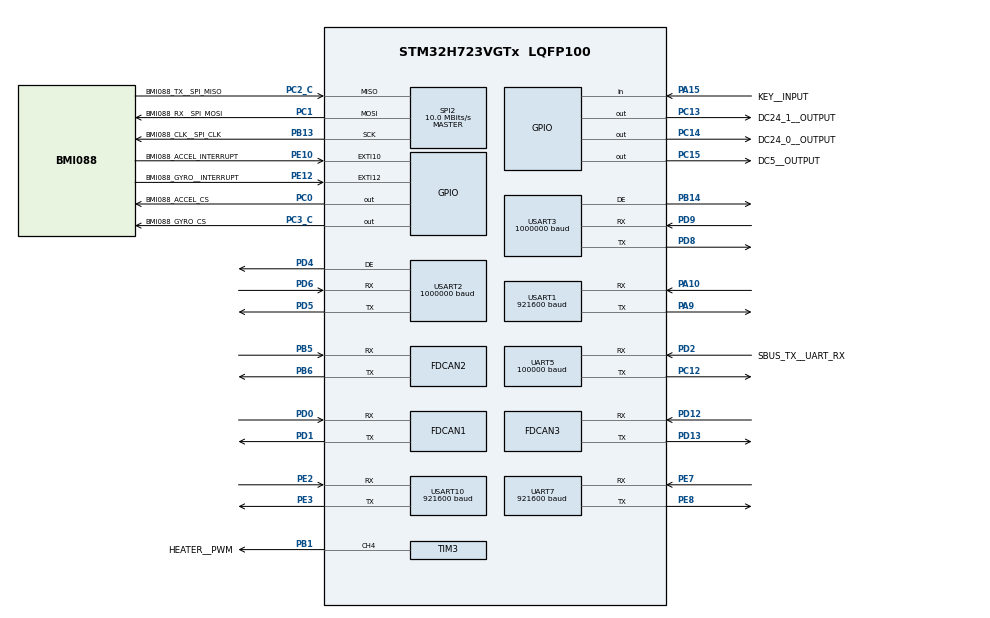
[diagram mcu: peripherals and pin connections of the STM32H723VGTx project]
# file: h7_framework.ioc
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CORTEX_M7.BaseAddress_Spec=0x24000000
CORTEX_M7.CPU_DCache=Disabled
CORTEX_M7.CPU_ICache=Enabled
CORTEX_M7.DisableExec_Spec=MPU_INSTRUCTION_ACCESS_ENABLE
CORTEX_M7.IsBufferable_Spec=MPU_ACCESS_BUFFERABLE
CORTEX_M7.IsCacheable_Spec=MPU_ACCESS_CACHEABLE
CORTEX_M7.IsShareable_Spec=MPU_ACCESS_NOT_SHAREABLE
CORTEX_M7.MPU_Control=__NULL
CORTEX_M7.Size_Spec=MPU_REGION_SIZE_512KB
CORTEX_M7.SubRegionDisable_Spec=0x0
CORTEX_M7.TypeExtField_Spec=MPU_TEX_LEVEL1
CORTEX_M7.default_mode_Activation=1
Dma.Request0=USART2_RX
Dma.Request1=USART2_TX
Dma.Request10=USART10_TX
Dma.Request11=SPI2_RX
Dma.Request12=SPI2_TX
Dma.Request2=USART3_RX
Dma.Request3=USART3_TX
Dma.Request4=UART5_RX
Dma.Request5=USART1_RX
Dma.Request6=USART1_TX
Dma.Request7=UART7_RX
Dma.Request8=UART7_TX
Dma.Request9=USART10_RX
Dma.SPI2_RX.11.Direction=DMA_PERIPH_TO_MEMORY
Dma.SPI2_RX.11.EventEnable=DISABLE
Dma.SPI2_RX.11.FIFOMode=DMA_FIFOMODE_ENABLE
Dma.SPI2_RX.11.FIFOThreshold=DMA_FIFO_THRESHOLD_FULL
Dma.SPI2_RX.11.Instance=DMA2_Stream3
Dma.SPI2_RX.11.MemBurst=DMA_MBURST_SINGLE
Dma.SPI2_RX.11.MemDataAlignment=DMA_MDATAALIGN_BYTE
Dma.SPI2_RX.11.MemInc=DMA_MINC_ENABLE
Dma.SPI2_RX.11.Mode=DMA_NORMAL
Dma.SPI2_RX.11.PeriphBurst=DMA_PBURST_SINGLE
Dma.SPI2_RX.11.PeriphDataAlignment=DMA_PDATAALIGN_BYTE
Dma.SPI2_RX.11.PeriphInc=DMA_PINC_DISABLE
Dma.SPI2_RX.11.Polarity=HAL_DMAMUX_REQ_GEN_RISING
Dma.SPI2_RX.11.Priority=DMA_PRIORITY_LOW
Dma.SPI2_RX.11.RequestNumber=1
Dma.SPI2_RX.11.SignalID=NONE
Dma.SPI2_RX.11.SyncEnable=DISABLE
Dma.SPI2_RX.11.SyncPolarity=HAL_DMAMUX_SYNC_NO_EVENT
Dma.SPI2_RX.11.SyncRequestNumber=1
Dma.SPI2_RX.11.SyncSignalID=NONE
Dma.SPI2_TX.12.Direction=DMA_MEMORY_TO_PERIPH
Dma.SPI2_TX.12.EventEnable=DISABLE
Dma.SPI2_TX.12.FIFOMode=DMA_FIFOMODE_DISABLE
Dma.SPI2_TX.12.Instance=DMA2_Stream4
Dma.SPI2_TX.12.MemDataAlignment=DMA_MDATAALIGN_BYTE
Dma.SPI2_TX.12.MemInc=DMA_MINC_ENABLE
Dma.SPI2_TX.12.Mode=DMA_NORMAL
Dma.SPI2_TX.12.PeriphDataAlignment=DMA_PDATAALIGN_BYTE
Dma.SPI2_TX.12.PeriphInc=DMA_PINC_DISABLE
Dma.SPI2_TX.12.Polarity=HAL_DMAMUX_REQ_GEN_RISING
Dma.SPI2_TX.12.Priority=DMA_PRIORITY_LOW
Dma.SPI2_TX.12.RequestNumber=1
Dma.SPI2_TX.12.SignalID=NONE
Dma.SPI2_TX.12.SyncEnable=DISABLE
Dma.SPI2_TX.12.SyncPolarity=HAL_DMAMUX_SYNC_NO_EVENT
Dma.SPI2_TX.12.SyncRequestNumber=1
Dma.SPI2_TX.12.SyncSignalID=NONE
Dma.UART5_RX.4.Direction=DMA_PERIPH_TO_MEMORY
Dma.UART5_RX.4.EventEnable=DISABLE
Dma.UART5_RX.4.FIFOMode=DMA_FIFOMODE_ENABLE
Dma.UART5_RX.4.FIFOThreshold=DMA_FIFO_THRESHOLD_FULL
Dma.UART5_RX.4.Instance=DMA1_Stream4
Dma.UART5_RX.4.MemBurst=DMA_MBURST_SINGLE
Dma.UART5_RX.4.MemDataAlignment=DMA_MDATAALIGN_BYTE
Dma.UART5_RX.4.MemInc=DMA_MINC_ENABLE
Dma.UART5_RX.4.Mode=DMA_NORMAL
Dma.UART5_RX.4.PeriphBurst=DMA_PBURST_SINGLE
Dma.UART5_RX.4.PeriphDataAlignment=DMA_PDATAALIGN_BYTE
Dma.UART5_RX.4.PeriphInc=DMA_PINC_DISABLE
Dma.UART5_RX.4.Polarity=HAL_DMAMUX_REQ_GEN_RISING
Dma.UART5_RX.4.Priority=DMA_PRIORITY_LOW
Dma.UART5_RX.4.RequestNumber=1
Dma.UART5_RX.4.SignalID=NONE
Dma.UART5_RX.4.SyncEnable=DISABLE
Dma.UART5_RX.4.SyncPolarity=HAL_DMAMUX_SYNC_NO_EVENT
Dma.UART5_RX.4.SyncRequestNumber=1
Dma.UART5_RX.4.SyncSignalID=NONE
Dma.UART7_RX.7.Direction=DMA_PERIPH_TO_MEMORY
Dma.UART7_RX.7.EventEnable=DISABLE
Dma.UART7_RX.7.FIFOMode=DMA_FIFOMODE_ENABLE
Dma.UART7_RX.7.FIFOThreshold=DMA_FIFO_THRESHOLD_FULL
Dma.UART7_RX.7.Instance=DMA1_Stream7
Dma.UART7_RX.7.MemBurst=DMA_MBURST_SINGLE
Dma.UART7_RX.7.MemDataAlignment=DMA_MDATAALIGN_BYTE
Dma.UART7_RX.7.MemInc=DMA_MINC_ENABLE
Dma.UART7_RX.7.Mode=DMA_NORMAL
Dma.UART7_RX.7.PeriphBurst=DMA_PBURST_SINGLE
Dma.UART7_RX.7.PeriphDataAlignment=DMA_PDATAALIGN_BYTE
Dma.UART7_RX.7.PeriphInc=DMA_PINC_DISABLE
Dma.UART7_RX.7.Polarity=HAL_DMAMUX_REQ_GEN_RISING
Dma.UART7_RX.7.Priority=DMA_PRIORITY_LOW
Dma.UART7_RX.7.RequestNumber=1
Dma.UART7_RX.7.SignalID=NONE
Dma.UART7_RX.7.SyncEnable=DISABLE
Dma.UART7_RX.7.SyncPolarity=HAL_DMAMUX_SYNC_NO_EVENT
Dma.UART7_RX.7.SyncRequestNumber=1
Dma.UART7_RX.7.SyncSignalID=NONE
Dma.UART7_TX.8.Direction=DMA_MEMORY_TO_PERIPH
Dma.UART7_TX.8.EventEnable=DISABLE
Dma.UART7_TX.8.FIFOMode=DMA_FIFOMODE_ENABLE
Dma.UART7_TX.8.FIFOThreshold=DMA_FIFO_THRESHOLD_FULL
Dma.UART7_TX.8.Instance=DMA2_Stream0
Dma.UART7_TX.8.MemBurst=DMA_MBURST_SINGLE
Dma.UART7_TX.8.MemDataAlignment=DMA_MDATAALIGN_BYTE
Dma.UART7_TX.8.MemInc=DMA_MINC_ENABLE
Dma.UART7_TX.8.Mode=DMA_NORMAL
Dma.UART7_TX.8.PeriphBurst=DMA_PBURST_SINGLE
Dma.UART7_TX.8.PeriphDataAlignment=DMA_PDATAALIGN_BYTE
Dma.UART7_TX.8.PeriphInc=DMA_PINC_DISABLE
Dma.UART7_TX.8.Polarity=HAL_DMAMUX_REQ_GEN_RISING
Dma.UART7_TX.8.Priority=DMA_PRIORITY_LOW
Dma.UART7_TX.8.RequestNumber=1
Dma.UART7_TX.8.SignalID=NONE
Dma.UART7_TX.8.SyncEnable=DISABLE
Dma.UART7_TX.8.SyncPolarity=HAL_DMAMUX_SYNC_NO_EVENT
Dma.UART7_TX.8.SyncRequestNumber=1
Dma.UART7_TX.8.SyncSignalID=NONE
Dma.USART10_RX.9.Direction=DMA_PERIPH_TO_MEMORY
Dma.USART10_RX.9.EventEnable=DISABLE
Dma.USART10_RX.9.FIFOMode=DMA_FIFOMODE_DISABLE
Dma.USART10_RX.9.Instance=DMA2_Stream1
Dma.USART10_RX.9.MemDataAlignment=DMA_MDATAALIGN_BYTE
Dma.USART10_RX.9.MemInc=DMA_MINC_ENABLE
Dma.USART10_RX.9.Mode=DMA_NORMAL
Dma.USART10_RX.9.PeriphDataAlignment=DMA_PDATAALIGN_BYTE
Dma.USART10_RX.9.PeriphInc=DMA_PINC_DISABLE
Dma.USART10_RX.9.Polarity=HAL_DMAMUX_REQ_GEN_RISING
Dma.USART10_RX.9.Priority=DMA_PRIORITY_LOW
Dma.USART10_RX.9.RequestNumber=1
Dma.USART10_RX.9.SignalID=NONE
Dma.USART10_RX.9.SyncEnable=DISABLE
Dma.USART10_RX.9.SyncPolarity=HAL_DMAMUX_SYNC_NO_EVENT
Dma.USART10_RX.9.SyncRequestNumber=1
Dma.USART10_RX.9.SyncSignalID=NONE
Dma.USART10_TX.10.Direction=DMA_MEMORY_TO_PERIPH
Dma.USART10_TX.10.EventEnable=DISABLE
Dma.USART10_TX.10.FIFOMode=DMA_FIFOMODE_DISABLE
Dma.USART10_TX.10.Instance=DMA2_Stream2
Dma.USART10_TX.10.MemDataAlignment=DMA_MDATAALIGN_BYTE
Dma.USART10_TX.10.MemInc=DMA_MINC_ENABLE
Dma.USART10_TX.10.Mode=DMA_NORMAL
Dma.USART10_TX.10.PeriphDataAlignment=DMA_PDATAALIGN_BYTE
Dma.USART10_TX.10.PeriphInc=DMA_PINC_DISABLE
Dma.USART10_TX.10.Polarity=HAL_DMAMUX_REQ_GEN_RISING
Dma.USART10_TX.10.Priority=DMA_PRIORITY_LOW
Dma.USART10_TX.10.RequestNumber=1
Dma.USART10_TX.10.SignalID=NONE
Dma.USART10_TX.10.SyncEnable=DISABLE
Dma.USART10_TX.10.SyncPolarity=HAL_DMAMUX_SYNC_NO_EVENT
Dma.USART10_TX.10.SyncRequestNumber=1
Dma.USART10_TX.10.SyncSignalID=NONE
Dma.USART1_RX.5.Direction=DMA_PERIPH_TO_MEMORY
Dma.USART1_RX.5.EventEnable=DISABLE
Dma.USART1_RX.5.FIFOMode=DMA_FIFOMODE_ENABLE
Dma.USART1_RX.5.FIFOThreshold=DMA_FIFO_THRESHOLD_FULL
Dma.USART1_RX.5.Instance=DMA1_Stream5
Dma.USART1_RX.5.MemBurst=DMA_MBURST_SINGLE
Dma.USART1_RX.5.MemDataAlignment=DMA_MDATAALIGN_BYTE
Dma.USART1_RX.5.MemInc=DMA_MINC_ENABLE
Dma.USART1_RX.5.Mode=DMA_NORMAL
Dma.USART1_RX.5.PeriphBurst=DMA_PBURST_SINGLE
Dma.USART1_RX.5.PeriphDataAlignment=DMA_PDATAALIGN_BYTE
Dma.USART1_RX.5.PeriphInc=DMA_PINC_DISABLE
Dma.USART1_RX.5.Polarity=HAL_DMAMUX_REQ_GEN_RISING
Dma.USART1_RX.5.Priority=DMA_PRIORITY_LOW
Dma.USART1_RX.5.RequestNumber=1
Dma.USART1_RX.5.SignalID=NONE
Dma.USART1_RX.5.SyncEnable=DISABLE
Dma.USART1_RX.5.SyncPolarity=HAL_DMAMUX_SYNC_NO_EVENT
Dma.USART1_RX.5.SyncRequestNumber=1
Dma.USART1_RX.5.SyncSignalID=NONE
Dma.USART1_TX.6.Direction=DMA_MEMORY_TO_PERIPH
Dma.USART1_TX.6.EventEnable=DISABLE
Dma.USART1_TX.6.FIFOMode=DMA_FIFOMODE_ENABLE
Dma.USART1_TX.6.FIFOThreshold=DMA_FIFO_THRESHOLD_FULL
Dma.USART1_TX.6.Instance=DMA1_Stream6
Dma.USART1_TX.6.MemBurst=DMA_MBURST_SINGLE
Dma.USART1_TX.6.MemDataAlignment=DMA_MDATAALIGN_BYTE
Dma.USART1_TX.6.MemInc=DMA_MINC_ENABLE
Dma.USART1_TX.6.Mode=DMA_NORMAL
Dma.USART1_TX.6.PeriphBurst=DMA_PBURST_SINGLE
Dma.USART1_TX.6.PeriphDataAlignment=DMA_PDATAALIGN_BYTE
Dma.USART1_TX.6.PeriphInc=DMA_PINC_DISABLE
Dma.USART1_TX.6.Polarity=HAL_DMAMUX_REQ_GEN_RISING
Dma.USART1_TX.6.Priority=DMA_PRIORITY_LOW
Dma.USART1_TX.6.RequestNumber=1
Dma.USART1_TX.6.SignalID=NONE
Dma.USART1_TX.6.SyncEnable=DISABLE
Dma.USART1_TX.6.SyncPolarity=HAL_DMAMUX_SYNC_NO_EVENT
Dma.USART1_TX.6.SyncRequestNumber=1
Dma.USART1_TX.6.SyncSignalID=NONE
Dma.USART2_RX.0.Direction=DMA_PERIPH_TO_MEMORY
Dma.USART2_RX.0.EventEnable=DISABLE
Dma.USART2_RX.0.FIFOMode=DMA_FIFOMODE_ENABLE
Dma.USART2_RX.0.FIFOThreshold=DMA_FIFO_THRESHOLD_FULL
Dma.USART2_RX.0.Instance=DMA1_Stream1
Dma.USART2_RX.0.MemBurst=DMA_MBURST_SINGLE
Dma.USART2_RX.0.MemDataAlignment=DMA_MDATAALIGN_BYTE
Dma.USART2_RX.0.MemInc=DMA_MINC_ENABLE
Dma.USART2_RX.0.Mode=DMA_NORMAL
Dma.USART2_RX.0.PeriphBurst=DMA_PBURST_SINGLE
Dma.USART2_RX.0.PeriphDataAlignment=DMA_PDATAALIGN_BYTE
Dma.USART2_RX.0.PeriphInc=DMA_PINC_DISABLE
Dma.USART2_RX.0.Polarity=HAL_DMAMUX_REQ_GEN_RISING
Dma.USART2_RX.0.Priority=DMA_PRIORITY_LOW
Dma.USART2_RX.0.RequestNumber=1
Dma.USART2_RX.0.SignalID=NONE
Dma.USART2_RX.0.SyncEnable=DISABLE
Dma.USART2_RX.0.SyncPolarity=HAL_DMAMUX_SYNC_NO_EVENT
Dma.USART2_RX.0.SyncRequestNumber=1
Dma.USART2_RX.0.SyncSignalID=NONE
Dma.USART2_TX.1.Direction=DMA_MEMORY_TO_PERIPH
Dma.USART2_TX.1.EventEnable=DISABLE
Dma.USART2_TX.1.FIFOMode=DMA_FIFOMODE_ENABLE
Dma.USART2_TX.1.FIFOThreshold=DMA_FIFO_THRESHOLD_FULL
Dma.USART2_TX.1.Instance=DMA1_Stream0
Dma.USART2_TX.1.MemBurst=DMA_MBURST_SINGLE
Dma.USART2_TX.1.MemDataAlignment=DMA_MDATAALIGN_BYTE
Dma.USART2_TX.1.MemInc=DMA_MINC_ENABLE
Dma.USART2_TX.1.Mode=DMA_NORMAL
Dma.USART2_TX.1.PeriphBurst=DMA_PBURST_SINGLE
Dma.USART2_TX.1.PeriphDataAlignment=DMA_PDATAALIGN_BYTE
Dma.USART2_TX.1.PeriphInc=DMA_PINC_DISABLE
Dma.USART2_TX.1.Polarity=HAL_DMAMUX_REQ_GEN_RISING
Dma.USART2_TX.1.Priority=DMA_PRIORITY_LOW
Dma.USART2_TX.1.RequestNumber=1
Dma.USART2_TX.1.SignalID=NONE
Dma.USART2_TX.1.SyncEnable=DISABLE
Dma.USART2_TX.1.SyncPolarity=HAL_DMAMUX_SYNC_NO_EVENT
Dma.USART2_TX.1.SyncRequestNumber=1
Dma.USART2_TX.1.SyncSignalID=NONE
Dma.USART3_RX.2.Direction=DMA_PERIPH_TO_MEMORY
Dma.USART3_RX.2.EventEnable=DISABLE
Dma.USART3_RX.2.FIFOMode=DMA_FIFOMODE_ENABLE
Dma.USART3_RX.2.FIFOThreshold=DMA_FIFO_THRESHOLD_FULL
Dma.USART3_RX.2.Instance=DMA1_Stream2
Dma.USART3_RX.2.MemBurst=DMA_MBURST_SINGLE
Dma.USART3_RX.2.MemDataAlignment=DMA_MDATAALIGN_BYTE
Dma.USART3_RX.2.MemInc=DMA_MINC_ENABLE
Dma.USART3_RX.2.Mode=DMA_NORMAL
Dma.USART3_RX.2.PeriphBurst=DMA_PBURST_SINGLE
Dma.USART3_RX.2.PeriphDataAlignment=DMA_PDATAALIGN_BYTE
Dma.USART3_RX.2.PeriphInc=DMA_PINC_DISABLE
Dma.USART3_RX.2.Polarity=HAL_DMAMUX_REQ_GEN_RISING
Dma.USART3_RX.2.Priority=DMA_PRIORITY_LOW
Dma.USART3_RX.2.RequestNumber=1
Dma.USART3_RX.2.SignalID=NONE
Dma.USART3_RX.2.SyncEnable=DISABLE
Dma.USART3_RX.2.SyncPolarity=HAL_DMAMUX_SYNC_NO_EVENT
Dma.USART3_RX.2.SyncRequestNumber=1
Dma.USART3_RX.2.SyncSignalID=NONE
Dma.USART3_TX.3.Direction=DMA_MEMORY_TO_PERIPH
Dma.USART3_TX.3.EventEnable=DISABLE
Dma.USART3_TX.3.FIFOMode=DMA_FIFOMODE_ENABLE
Dma.USART3_TX.3.FIFOThreshold=DMA_FIFO_THRESHOLD_FULL
Dma.USART3_TX.3.Instance=DMA1_Stream3
Dma.USART3_TX.3.MemBurst=DMA_MBURST_SINGLE
Dma.USART3_TX.3.MemDataAlignment=DMA_MDATAALIGN_BYTE
Dma.USART3_TX.3.MemInc=DMA_MINC_ENABLE
Dma.USART3_TX.3.Mode=DMA_NORMAL
Dma.USART3_TX.3.PeriphBurst=DMA_PBURST_SINGLE
Dma.USART3_TX.3.PeriphDataAlignment=DMA_PDATAALIGN_BYTE
Dma.USART3_TX.3.PeriphInc=DMA_PINC_DISABLE
Dma.USART3_TX.3.Polarity=HAL_DMAMUX_REQ_GEN_RISING
Dma.USART3_TX.3.Priority=DMA_PRIORITY_LOW
Dma.USART3_TX.3.RequestNumber=1
Dma.USART3_TX.3.SignalID=NONE
Dma.USART3_TX.3.SyncEnable=DISABLE
Dma.USART3_TX.3.SyncPolarity=HAL_DMAMUX_SYNC_NO_EVENT
Dma.USART3_TX.3.SyncRequestNumber=1
Dma.USART3_TX.3.SyncSignalID=NONE
FDCAN1.AutoRetransmission=ENABLE
FDCAN1.CalculateBaudRateNominal=1000000
FDCAN1.CalculateTimeBitNominal=1000
FDCAN1.CalculateTimeQuantumNominal=25.0
FDCAN1.DataPrescaler=3
FDCAN1.DataSyncJumpWidth=10
FDCAN1.DataTimeSeg1=29
FDCAN1.DataTimeSeg2=10
FDCAN1.NominalPrescaler=3
FDCAN1.NominalSyncJumpWidth=10
FDCAN1.NominalTimeSeg1=29
FDCAN1.NominalTimeSeg2=10
FDCAN1.ProtocolException=DISABLE
FDCAN1.RxFifo0ElmtsNbr=16
FDCAN1.RxFifo1ElmtsNbr=0
FDCAN1.StdFiltersNbr=1
FDCAN1.TxFifoQueueElmtsNbr=8
FDCAN2.AutoRetransmission=ENABLE
FDCAN2.CalculateBaudRateNominal=1000000
FDCAN2.CalculateTimeBitNominal=1000
FDCAN2.CalculateTimeQuantumNominal=25.0
FDCAN2.DataPrescaler=3
FDCAN2.DataSyncJumpWidth=10
FDCAN2.DataTimeSeg1=29
FDCAN2.DataTimeSeg2=10
FDCAN2.MessageRAMOffset=853
FDCAN2.NominalPrescaler=3
FDCAN2.NominalSyncJumpWidth=10
FDCAN2.NominalTimeSeg1=29
FDCAN2.NominalTimeSeg2=10
FDCAN2.RxFifo0ElmtsNbr=16
FDCAN2.RxFifo1ElmtsNbr=0
FDCAN2.StdFiltersNbr=1
FDCAN2.TxFifoQueueElmtsNbr=8
FDCAN3.AutoRetransmission=ENABLE
FDCAN3.CalculateBaudRateNominal=1000000
FDCAN3.CalculateTimeBitNominal=1000
FDCAN3.CalculateTimeQuantumNominal=25.0
FDCAN3.DataPrescaler=3
FDCAN3.DataSyncJumpWidth=10
FDCAN3.DataTimeSeg1=29
FDCAN3.DataTimeSeg2=10
FDCAN3.MessageRAMOffset=1706
FDCAN3.NominalPrescaler=3
FDCAN3.NominalSyncJumpWidth=10
FDCAN3.NominalTimeSeg1=29
FDCAN3.NominalTimeSeg2=10
FDCAN3.RxFifo0ElmtsNbr=16
FDCAN3.RxFifo1ElmtsNbr=0
FDCAN3.StdFiltersNbr=1
FDCAN3.TxFifoQueueElmtsNbr=8
FREERTOS.Tasks01=Manager,16,512,StartManger,As weak,NULL,Dynamic,NULL,NULL;Gimbal,32,1024,StartGimbal,As weak,NULL,Dynamic,NULL,NULL;Chassis,24,512,StartChassis,As weak,NULL,Dynamic,NULL,NULL;Shoot,24,512,StartShoot,As weak,NULL,Dynamic,NULL,NULL
Mcu.Family=STM32H7
Mcu.Name=STM32H723VGTx
Mcu.Package=LQFP100
NVIC.DMA1_Stream0_IRQn=true\:5\:0\:false\:false\:true\:true\:false\:true\:true
NVIC.DMA1_Stream1_IRQn=true\:5\:0\:false\:false\:true\:true\:false\:true\:true
NVIC.DMA1_Stream2_IRQn=true\:5\:0\:false\:false\:true\:true\:false\:true\:true
NVIC.DMA1_Stream3_IRQn=true\:5\:0\:false\:false\:true\:true\:false\:true\:true
NVIC.DMA1_Stream4_IRQn=true\:5\:0\:false\:false\:true\:true\:false\:true\:true
NVIC.DMA1_Stream5_IRQn=true\:5\:0\:false\:false\:true\:true\:false\:true\:true
NVIC.DMA1_Stream6_IRQn=true\:5\:0\:false\:false\:true\:true\:false\:true\:true
NVIC.DMA1_Stream7_IRQn=true\:5\:0\:false\:false\:true\:true\:false\:true\:true
NVIC.DMA2_Stream0_IRQn=true\:5\:0\:false\:false\:true\:true\:false\:true\:true
NVIC.DMA2_Stream1_IRQn=true\:5\:0\:false\:false\:true\:true\:false\:true\:true
NVIC.DMA2_Stream2_IRQn=true\:5\:0\:false\:false\:true\:true\:false\:true\:true
NVIC.DMA2_Stream3_IRQn=true\:5\:0\:false\:false\:true\:true\:false\:true\:true
NVIC.DMA2_Stream4_IRQn=true\:5\:0\:false\:false\:true\:true\:false\:true\:true
NVIC.EXTI15_10_IRQn=true\:5\:0\:true\:false\:true\:true\:true\:true\:true
NVIC.FDCAN1_IT0_IRQn=true\:5\:0\:false\:false\:true\:true\:true\:true\:true
NVIC.FDCAN1_IT1_IRQn=true\:5\:0\:false\:false\:true\:true\:true\:true\:true
NVIC.FDCAN2_IT0_IRQn=true\:5\:0\:false\:false\:true\:true\:true\:true\:true
NVIC.FDCAN2_IT1_IRQn=true\:5\:0\:false\:false\:true\:true\:true\:true\:true
NVIC.FDCAN3_IT0_IRQn=true\:5\:0\:false\:false\:true\:true\:true\:true\:true
NVIC.FDCAN3_IT1_IRQn=true\:5\:0\:false\:false\:true\:true\:true\:true\:true
NVIC.PriorityGroup=NVIC_PRIORITYGROUP_4
NVIC.SPI2_IRQn=true\:5\:0\:false\:false\:true\:true\:false\:true\:true
NVIC.TIM6_DAC_IRQn=true\:15\:0\:false\:false\:true\:false\:false\:true\:true
NVIC.TimeBase=TIM6_DAC_IRQn
NVIC.TimeBaseIP=TIM6
NVIC.UART5_IRQn=true\:5\:0\:true\:false\:true\:true\:true\:true\:true
NVIC.UART7_IRQn=true\:5\:0\:true\:false\:true\:true\:true\:true\:true
NVIC.USART10_IRQn=true\:5\:0\:true\:false\:true\:true\:true\:true\:true
NVIC.USART1_IRQn=true\:5\:0\:true\:false\:true\:true\:true\:true\:true
NVIC.USART2_IRQn=true\:5\:0\:true\:false\:true\:true\:true\:true\:true
NVIC.USART3_IRQn=true\:5\:0\:true\:false\:true\:true\:true\:true\:true
PA1.GPIO_Label=W25Q64_HOLD__OSPI_IO3
PA1.Signal=OCTOSPIM_P1_IO3
PA10.Mode=Asynchronous
PA10.Signal=USART1_RX
PA13(JTMS/SWDIO).Mode=Serial_Wire
PA13(JTMS/SWDIO).Signal=DEBUG_JTMS-SWDIO
PA14(JTCK/SWCLK).Mode=Serial_Wire
PA14(JTCK/SWCLK).Signal=DEBUG_JTCK-SWCLK
PA15(JTDI).GPIO_Label=KEY__INPUT
PA15(JTDI).Signal=GPIO_Input
PA2.GPIO_Label=SERVO_2__PWM
PA2.Signal=S_TIM2_CH3
PA3.GPIO_Label=W25Q64_WP__OSPI_IO2
PA3.Signal=OCTOSPIM_P1_IO2
PA9.Mode=Asynchronous
PA9.Signal=USART1_TX
PB0.GPIO_Label=W25Q64_SO__OSPI_IO1
PB0.Signal=OCTOSPIM_P1_IO1
PB1.GPIO_Label=HEATER__PWM
PB1.Signal=S_TIM3_CH4
PB13.GPIO_Label=BMI088_CLK__SPI_CLK
PB13.GPIO_Speed=GPIO_SPEED_FREQ_VERY_HIGH
PB13.Mode=Full_Duplex_Master
PB13.Signal=SPI2_SCK
PB14.Mode=Hardware Flow Control (RS485)
PB14.Signal=USART3_DE
PB5.Mode=FDCAN_Activate
PB5.Signal=FDCAN2_RX
PB6.Mode=FDCAN_Activate
PB6.Signal=FDCAN2_TX
PC0.GPIO_Label=BMI088_ACCEL_CS
PC0.GPIO_Speed=GPIO_SPEED_FREQ_VERY_HIGH
PC0.PinState=GPIO_PIN_SET
PC0.Signal=GPIO_Output
PC1.GPIO_Label=BMI088_RX__SPI_MOSI
PC1.GPIO_Speed=GPIO_SPEED_FREQ_VERY_HIGH
PC1.Mode=Full_Duplex_Master
PC1.Signal=SPI2_MOSI
PC12.Mode=Asynchronous
PC12.Signal=UART5_TX
PC13.GPIO_Label=DC24_1__OUTPUT
PC13.PinState=GPIO_PIN_SET
PC13.Signal=GPIO_Output
PC14-OSC32_IN.GPIO_Label=DC24_0__OUTPUT
PC14-OSC32_IN.PinState=GPIO_PIN_SET
PC14-OSC32_IN.Signal=GPIO_Output
PC15-OSC32_OUT.GPIO_Label=DC5__OUTPUT
PC15-OSC32_OUT.PinState=GPIO_PIN_SET
PC15-OSC32_OUT.Signal=GPIO_Output
PC2_C.GPIO_Label=BMI088_TX__SPI_MISO
PC2_C.GPIO_Speed=GPIO_SPEED_FREQ_VERY_HIGH
PC2_C.Mode=Full_Duplex_Master
PC2_C.Signal=SPI2_MISO
PC3_C.GPIO_Label=BMI088_GYRO_CS
PC3_C.GPIO_Speed=GPIO_SPEED_FREQ_VERY_HIGH
PC3_C.PinState=GPIO_PIN_SET
PC3_C.Signal=GPIO_Output
PC4.GPIO_Label=BAT_VOLTAGE__ADC
PC4.Signal=ADCx_INP4
PD0.Mode=FDCAN_Activate
PD0.Signal=FDCAN1_RX
PD1.Mode=FDCAN_Activate
PD1.Signal=FDCAN1_TX
PD11.GPIO_Label=W25Q64_SI__OSPI_IO0
PD11.Signal=OCTOSPIM_P1_IO0
PD12.Mode=FDCAN_Activate
PD12.Signal=FDCAN3_RX
PD13.Mode=FDCAN_Activate
PD13.Signal=FDCAN3_TX
PD2.GPIO_Label=SBUS_TX__UART_RX
PD2.Mode=Asynchronous
PD2.Signal=UART5_RX
PD4.Mode=Hardware Flow Control (RS485)
PD4.Signal=USART2_DE
PD5.Mode=Asynchronous
PD5.Signal=USART2_TX
PD6.Mode=Asynchronous
PD6.Signal=USART2_RX
PD8.Mode=Asynchronous
PD8.Signal=USART3_TX
PD9.Mode=Asynchronous
PD9.Signal=USART3_RX
PE10.GPIO_Label=BMI088_ACCEL_INTERRUPT
PE10.Signal=GPXTI10
PE12.GPIO_Label=BMI088_GYRO__INTERRUPT
PE12.Signal=GPXTI12
PE13.GPIO_Label=SERVO_0__PWM
PE13.Signal=S_TIM1_CH3
PE2.Mode=Asynchronous
PE2.Signal=USART10_RX
PE3.Mode=Asynchronous
PE3.Signal=USART10_TX
PE7.Mode=Asynchronous
PE7.Signal=UART7_RX
PE8.Mode=Asynchronous
PE8.Signal=UART7_TX
PE9.GPIO_Label=SERVO_1__PWM
PE9.Signal=S_TIM1_CH1
PH0-OSC_IN.Mode=HSE-External-Oscillator
PH0-OSC_IN.Signal=RCC_OSC_IN
PH1-OSC_OUT.Mode=HSE-External-Oscillator
PH1-OSC_OUT.Signal=RCC_OSC_OUT
ProjectManager.HeapSize=0x5000
ProjectManager.StackSize=0x5000
ProjectManager.TargetToolchain=CMake
RCC.ADCCLockSelection=RCC_ADCCLKSOURCE_CLKP
RCC.ADCFreq_Value=24000000
RCC.APB1Freq_Value=120000000
RCC.APB2Freq_Value=120000000
RCC.APB3Freq_Value=120000000
RCC.APB4Freq_Value=120000000
RCC.CKPERSourceSelection=RCC_CLKPSOURCE_HSE
RCC.CortexFreq_Value=480000000
RCC.D1PPRE=RCC_APB3_DIV2
RCC.D2PPRE1=RCC_APB1_DIV2
RCC.D2PPRE2=RCC_APB2_DIV2
RCC.D3PPRE=RCC_APB4_DIV2
RCC.DIVM1=2
RCC.DIVM2=12
RCC.DIVM3=24
RCC.DIVN1=40
RCC.DIVN2=100
RCC.DIVN3=160
RCC.DIVP1=1
RCC.DIVQ1=4
RCC.DIVQ2=4
RCC.HCLKFreq_Value=240000000
RCC.HPRE=RCC_HCLK_DIV2
RCC.HSE_VALUE=24000000
RCC.PLL2FRACN=0
RCC.PLLFRACN=0
RCC.PLLSourceVirtual=RCC_PLLSOURCE_HSE
RCC.SPI123CLockSelection=RCC_SPI123CLKSOURCE_PLL3
RCC.SPI6CLockSelection=RCC_SPI6CLKSOURCE_PLL2
RCC.SYSCLKFreq_VALUE=480000000
RCC.SYSCLKSource=RCC_SYSCLKSOURCE_PLLCLK
RCC.USBCLockSelection=RCC_USBCLKSOURCE_HSI48
RCC.USBFreq_Value=48000000
SH.ADCx_INP4.0=ADC1_INP4
SH.S_TIM1_CH1.0=TIM1_CH1
SH.S_TIM1_CH3.0=TIM1_CH3
SH.S_TIM2_CH3.0=TIM2_CH3
SH.S_TIM3_CH4.0=TIM3_CH4,PWM Generation4 CH4
SPI2.BaudRatePrescaler=SPI_BAUDRATEPRESCALER_8
SPI2.CLKPhase=SPI_PHASE_2EDGE
SPI2.CLKPolarity=SPI_POLARITY_HIGH
SPI2.CalculateBaudRate=10.0 MBits/s
SPI2.DataSize=SPI_DATASIZE_8BIT
SPI2.Direction=SPI_DIRECTION_2LINES
SPI2.Mode=SPI_MODE_MASTER
SPI2.VirtualType=VM_MASTER
TIM3.Channel-PWM\ Generation4\ CH4=TIM_CHANNEL_4
TIM3.Period=10000-1
TIM3.Prescaler=240-1
UART5.BaudRate=100000
UART5.Mode=MODE_RX
UART5.Parity=PARITY_EVEN
UART5.StopBits=UART_STOPBITS_2
UART5.WordLength=WORDLENGTH_9B
UART7.BaudRate=921600
USART1.BaudRate=921600
USART1.VirtualMode-Asynchronous=VM_ASYNC
USART10.BaudRate=921600
USART10.VirtualMode=VM_ASYNC
USART2.BaudRate=1000000
USART2.VirtualMode-Asynchronous=VM_ASYNC
USART2.VirtualMode-Hardware\ Flow\ Control\ (RS485)=VM_ASYNC
USART3.BaudRate=1000000
USART3.VirtualMode-Asynchronous=VM_ASYNC
USART3.VirtualMode-Hardware\ Flow\ Control\ (RS485)=VM_ASYNC
VP_FREERTOS_VS_CMSIS_V2.Mode=CMSIS_V2
VP_MEMORYMAP_VS_MEMORYMAP.Mode=CurAppReg
VP_SYS_VS_tim6.Mode=TIM6
board=custom

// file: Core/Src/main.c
/* USER CODE BEGIN Header */
/**
  ******************************************************************************
  * @file           : main.c
  * @brief          : Main program body
  ******************************************************************************
  * @attention
  *
  * Copyright (c) 2026 STMicroelectronics.
  * All rights reserved.
  *
  * This software is licensed under terms that can be found in the LICENSE file
  * in the root directory of this software component.
  * If no LICENSE file comes with this software, it is provided AS-IS.
  *
  ******************************************************************************
  */
/* USER CODE END Header */
#include "main.h"
#include "FreeRTOS.h"
#include "cmsis_os2.h"
#include "dma.h"
#include "fdcan.h"
#include "spi.h"
#include "tim.h"
#include "usart.h"
#include "gpio.h"

void SystemClock_Config(void);
void MX_FREERTOS_Init(void);

int main(void)
{

  /* Enable the CPU Cache */

  /* Enable I-Cache---------------------------------------------------------*/
  SCB_EnableICache();

  /* MCU Configuration--------------------------------------------------------*/

  /* Reset of all peripherals, Initializes the Flash interface and the Systick. */
  HAL_Init();

  /* Configure the system clock */
  SystemClock_Config();

  /* Initialize all configured peripherals */
  MX_GPIO_Init();
  MX_DMA_Init();
  MX_FDCAN1_Init();
  MX_FDCAN2_Init();
  MX_FDCAN3_Init();
  MX_USART1_UART_Init();
  MX_USART2_UART_Init();
  MX_USART3_UART_Init();
  MX_UART5_Init();
  MX_UART7_Init();
  MX_USART10_UART_Init();
  MX_SPI2_Init();
  MX_TIM3_Init();

  /* Init scheduler */
  osKernelInitialize();  /* Call init function for freertos objects (in cmsis_os2.c) */
  MX_FREERTOS_Init();

  /* Start scheduler */
  osKernelStart();

  /* We should never get here as control is now taken by the scheduler */

  /* Infinite loop */
  while (1)
  {

  }
}

void SystemClock_Config(void)
{
  RCC_OscInitTypeDef RCC_OscInitStruct = {0};
  RCC_ClkInitTypeDef RCC_ClkInitStruct = {0};

  /** Supply configuration update enable
  */
  HAL_PWREx_ConfigSupply(PWR_LDO_SUPPLY);

  /** Configure the main internal regulator output voltage
  */
  __HAL_PWR_VOLTAGESCALING_CONFIG(PWR_REGULATOR_VOLTAGE_SCALE0);

  while(!__HAL_PWR_GET_FLAG(PWR_FLAG_VOSRDY)) {}

  /** Initializes the RCC Oscillators according to the specified parameters
  * in the RCC_OscInitTypeDef structure.
  */
  RCC_OscInitStruct.OscillatorType = RCC_OSCILLATORTYPE_HSE;
  RCC_OscInitStruct.HSEState = RCC_HSE_ON;
  RCC_OscInitStruct.PLL.PLLState = RCC_PLL_ON;
  RCC_OscInitStruct.PLL.PLLSource = RCC_PLLSOURCE_HSE;
  RCC_OscInitStruct.PLL.PLLM = 2;
  RCC_OscInitStruct.PLL.PLLN = 40;
  RCC_OscInitStruct.PLL.PLLP = 1;
  RCC_OscInitStruct.PLL.PLLQ = 4;
  RCC_OscInitStruct.PLL.PLLR = 2;
  RCC_OscInitStruct.PLL.PLLRGE = RCC_PLL1VCIRANGE_3;
  RCC_OscInitStruct.PLL.PLLVCOSEL = RCC_PLL1VCOWIDE;
  RCC_OscInitStruct.PLL.PLLFRACN = 0;
  if (HAL_RCC_OscConfig(&RCC_OscInitStruct) != HAL_OK)
  {
    Error_Handler();
  }

  /** Initializes the CPU, AHB and APB buses clocks
  */
  RCC_ClkInitStruct.ClockType = RCC_CLOCKTYPE_HCLK|RCC_CLOCKTYPE_SYSCLK
                              |RCC_CLOCKTYPE_PCLK1|RCC_CLOCKTYPE_PCLK2
                              |RCC_CLOCKTYPE_D3PCLK1|RCC_CLOCKTYPE_D1PCLK1;
  RCC_ClkInitStruct.SYSCLKSource = RCC_SYSCLKSOURCE_PLLCLK;
  RCC_ClkInitStruct.SYSCLKDivider = RCC_SYSCLK_DIV1;
  RCC_ClkInitStruct.AHBCLKDivider = RCC_HCLK_DIV2;
  RCC_ClkInitStruct.APB3CLKDivider = RCC_APB3_DIV2;
  RCC_ClkInitStruct.APB1CLKDivider = RCC_APB1_DIV2;
  RCC_ClkInitStruct.APB2CLKDivider = RCC_APB2_DIV2;
  RCC_ClkInitStruct.APB4CLKDivider = RCC_APB4_DIV2;

  if (HAL_RCC_ClockConfig(&RCC_ClkInitStruct, FLASH_LATENCY_3) != HAL_OK)
  {
    Error_Handler();
  }
}

void HAL_TIM_PeriodElapsedCallback(TIM_HandleTypeDef *htim)
{
  if (htim->Instance == TIM6)
  {
    HAL_IncTick();
  }
}

void Error_Handler(void)
{
  __disable_irq();
  while (1)
  {
  }
}

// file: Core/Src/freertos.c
/* USER CODE BEGIN Header */
/**
  ******************************************************************************
  * File Name          : freertos.c
  * Description        : Code for freertos applications
  ******************************************************************************
  * @attention
  *
  * Copyright (c) 2026 STMicroelectronics.
  * All rights reserved.
  *
  * This software is licensed under terms that can be found in the LICENSE file
  * in the root directory of this software component.
  * If no LICENSE file comes with this software, it is provided AS-IS.
  *
  ******************************************************************************
  */
/* USER CODE END Header */

#include "FreeRTOS.h"
#include "task.h"
#include "main.h"
#include "FreeRTOS.h"
#include "cmsis_os2.h"

/* USER CODE BEGIN Includes */
#include "app_config.h"
/* USER CODE END Includes */

/* Definitions for Manager */
osThreadId_t ManagerHandle;
const osThreadAttr_t Manager_attributes = {
  .name = "Manager",
  .stack_size = 512 * 4,
  .priority = (osPriority_t) osPriorityBelowNormal,
};
/* Definitions for Gimbal */
osThreadId_t GimbalHandle;
const osThreadAttr_t Gimbal_attributes = {
  .name = "Gimbal",
  .stack_size = 1024 * 4,
  .priority = (osPriority_t) osPriorityAboveNormal,
};
/* Definitions for Chassis */
osThreadId_t ChassisHandle;
const osThreadAttr_t Chassis_attributes = {
  .name = "Chassis",
  .stack_size = 512 * 4,
  .priority = (osPriority_t) osPriorityNormal,
};
/* Definitions for Shoot */
osThreadId_t ShootHandle;
const osThreadAttr_t Shoot_attributes = {
  .name = "Shoot",
  .stack_size = 512 * 4,
  .priority = (osPriority_t) osPriorityNormal,
};

void StartManger(void *argument);
void StartGimbal(void *argument);
void StartChassis(void *argument);
void StartShoot(void *argument);

void MX_FREERTOS_Init(void); /* (MISRA C 2004 rule 8.1) */

void MX_FREERTOS_Init(void) {
  /* USER CODE BEGIN Init */
  AppConfigInit();
  /* USER CODE END Init */

  /* Create the thread(s) */
  /* creation of Manager */
  ManagerHandle = osThreadNew(StartManger, NULL, &Manager_attributes);

  /* creation of Gimbal */
  GimbalHandle = osThreadNew(StartGimbal, NULL, &Gimbal_attributes);

  /* creation of Chassis */
  ChassisHandle = osThreadNew(StartChassis, NULL, &Chassis_attributes);

  /* creation of Shoot */
  ShootHandle = osThreadNew(StartShoot, NULL, &Shoot_attributes);

}

__weak void StartManger(void *argument)
{
  for(;;)
  {
    osDelay(1);
  }
}

__weak void StartGimbal(void *argument)
{
  for(;;)
  {
    osDelay(1);
  }
}

__weak void StartChassis(void *argument)
{
  for(;;)
  {
    osDelay(1);
  }
}

__weak void StartShoot(void *argument)
{
  for(;;)
  {
    osDelay(1);
  }
}
